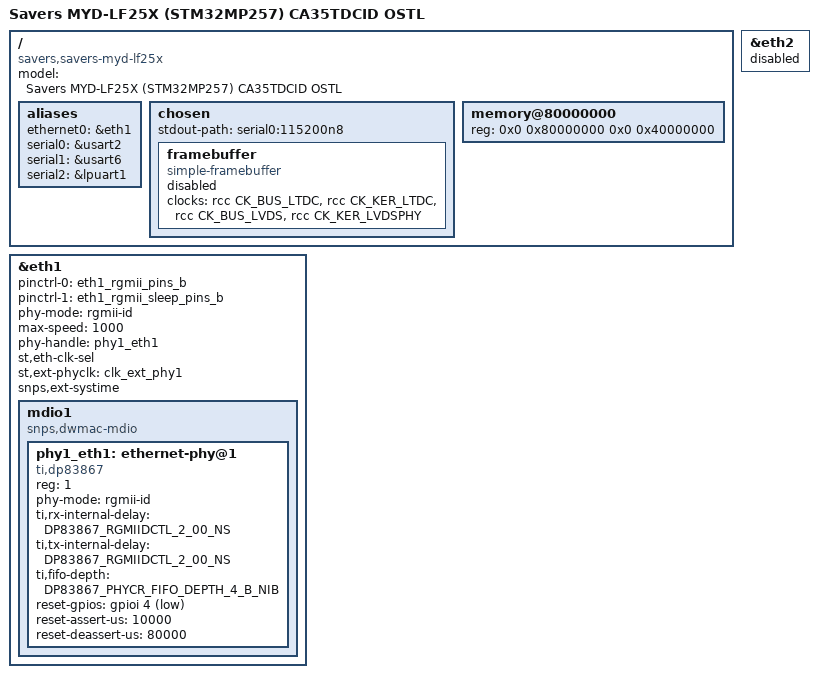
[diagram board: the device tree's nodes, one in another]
// SPDX-License-Identifier: (GPL-2.0-only OR BSD-3-Clause)
/*
 * Copyright (C) Savers 2024 - All Rights Reserved
 *
 * Savers MYD-LF25X (U-Boot / CA35TDCID OSTL).
 *
 * Re-based onto MYiR's vanilla u-boot myb-stm32mp257x-1GB device tree (myb-base
 * + 1GB-resmem). The Savers carrier uses a single TI DP83867 on eth1 instead of
 * MYiR's dual Motorcomm YT8531 PHYs, so the eth1 MDIO bus from myb-base is
 * deleted and replaced below.
 *
 * Reserved-memory comes from MYiR's myb-stm32mp257x-1GB-resmem.dtsi to match the
 * rebased OP-TEE / Linux device trees.
 *
 * SoM: MYiR MYD-LF25X, STM32MP257F, 1GB LPDDR4.
 */

/dts-v1/;

#include <dt-bindings/net/ti-dp83867.h>
#include "myb-stm32mp257x-base.dtsi"
#include "myb-stm32mp257x-1GB-resmem.dtsi"

/ {
	model = "Savers MYD-LF25X (STM32MP257) CA35TDCID OSTL";
	compatible = "savers,savers-myd-lf25x", "st,myb-stm32mp257x-1GB",
		     "myir,myb-stm32mp257x-1GB", "st,stm32mp257";

	aliases {
		ethernet0 = &eth1;
		serial0 = &usart2;
		serial1 = &usart6;
		serial2 = &lpuart1;
	};

	chosen {
		stdout-path = "serial0:115200n8";
		#address-cells = <2>;
		#size-cells = <2>;
		ranges;

		framebuffer {
			compatible = "simple-framebuffer";
			clocks = <&rcc CK_BUS_LTDC>, <&rcc CK_KER_LTDC>,
				 <&rcc CK_BUS_LVDS>, <&rcc CK_KER_LVDSPHY>;
			status = "disabled";
		};
	};

	memory@80000000 {
		device_type = "memory";
		reg = <0x0 0x80000000 0x0 0x40000000>;
	};
};

/*
 * Savers Ethernet: single TI DP83867 on eth1 at MDIO address 1, using the
 * STM32MP257F-DK RGMII/MDIO pin group (eth1_rgmii_pins_b also carries MDC/MDIO).
 * Replaces MYiR's dual Motorcomm PHYs from myb-base; eth2 is unused.
 */
&eth1 {
	status = "okay";
	pinctrl-0 = <&eth1_rgmii_pins_b>;
	pinctrl-1 = <&eth1_rgmii_sleep_pins_b>;
	pinctrl-names = "default", "sleep";
	phy-mode = "rgmii-id";
	max-speed = <1000>;
	phy-handle = <&phy1_eth1>;
	st,eth-clk-sel;
	st,ext-phyclk = <&clk_ext_phy1>;
	snps,ext-systime;

	/* Drop MYiR's dual-Motorcomm MDIO bus and replace with the DP83867. */
	/delete-node/ mdio1;

	mdio1 {
		#address-cells = <1>;
		#size-cells = <0>;
		compatible = "snps,dwmac-mdio";

		phy1_eth1: ethernet-phy@1 {
			compatible = "ti,dp83867";
			reg = <1>;
			phy-mode = "rgmii-id";
			ti,rx-internal-delay = <DP83867_RGMIIDCTL_2_00_NS>;
			ti,tx-internal-delay = <DP83867_RGMIIDCTL_2_00_NS>;
			ti,fifo-depth = <DP83867_PHYCR_FIFO_DEPTH_4_B_NIB>;
			reset-gpios = <&gpioi 4 GPIO_ACTIVE_LOW>;	/* ETH1_PHY_RST (PI4) */
			reset-assert-us = <10000>;
			reset-deassert-us = <80000>;
		};
	};
};

&eth2 {
	status = "disabled";
};
